# A31C15x register map
Vendor: ABOV Semiconductor Co., Ltd.; File version: 1.0
CPU: CM0PLUS r0p1, little endian, no MPU, no FPU, VTOR, 2 interrupt priority bits
Registers are 32-bit, read-write, reset 0x0 unless marked. A register's access mark holds for its fields unless they carry their own. Offsets are from the block's base; [hi:lo] are bit positions.

## RTCC — Real-time clock
Base 0x40000900
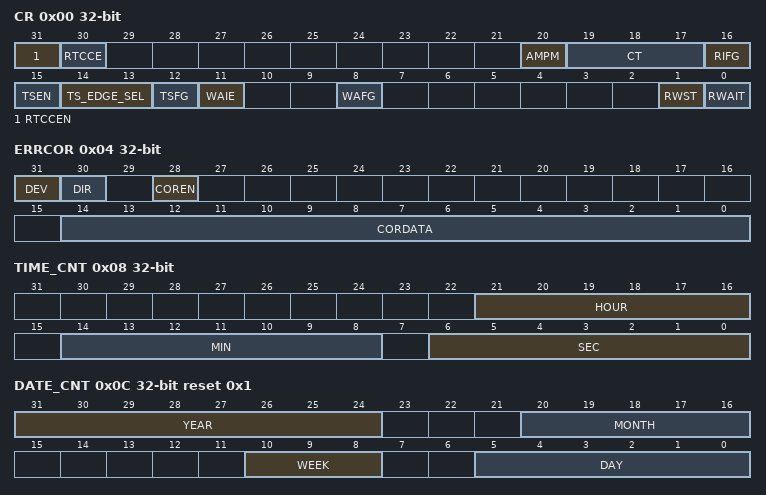
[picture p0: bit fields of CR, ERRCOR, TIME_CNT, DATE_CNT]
0x00 CR — RTCC Control Register
  [31] RTCCEN — RTCC clock input enable
  [30] RTCCE — RTCC counter run
  [20] AMPM — Hour system selection
  [19:17] CT — Period selection of constant-period matching
  [16] RIFG — Constant-period matching flag
  [15] TSEN — Timestamp enable
  [14:13] TS_EDGE_SEL — Timestamp event active edge selection
  [12] TSFG — Time stamp event flag
  [11] WAIE — Alarm enable
  [8] WAFG — Alarm flag
  [1] RWST — RW mode status flag
  [0] RWAIT — RW mode set
0x04 ERRCOR — RTCC Error Correction Register
  [31] DEV — Setting of watch error correction timing.
  [30] DIR — Setting of watch error correction direction
  [28] COREN — Enable watch error correction
  [14:0] CORDATA — Setting of watch error correction data When CORDATA=0, the watch error is not corrected.
0x08 TIME_CNT — RTCC Time Count Register
  [21:16] HOUR — The HOUR register is an 8-bit register that takes a value of 00 to 23 or 01 to 12 and 21 to 32 (decimal) and indicates the count value of hours. It counts up when the minute counter overflows.
  [14:8] MIN — The MIN register is an 8-bit register that takes a value of 0 to 59 (decimal) and indicates the count value of minutes. It counts up when the second counter overflows. When data is written to this register, it is written to a buffer and then to the counter when RWST bit is changed to '0'. Even if the second count register overflows while this register is being written, this register ignores the overflow and is set to the value written. Set a decimal value of 00 to 59 to this register in BCD code. If a value that is not a BCD code is written, it is ignored. If a value outside the range is written, the reset value is set.
  [6:0] SEC — The SEC register is an 8-bit register that takes a value of 0 to 59 (decimal) and indicates the count value of seconds. It counts up when the sub-count register overflows. When data is written to this register, it is written to a buffer and then to the counter when RWST bit is changed to '0'. Set a decimal value of 00 to 59 to this register in BCD code. If a value that is not a BCD code is written, it is ignored. If a value outside the range is written, the reset value is set.
0x0C DATE_CNT reset 0x1 — RTCC Date Count Register
  [31:24] YEAR — The YEAR register is an 8-bit register that takes a value of 0 to 99 (decimal) and indicates the count value of years.
  [20:16] MONTH — The MONTH register is an 8-bit register that takes a value of 1 to 12 (decimal) and indicates the count value of months. It counts up when the day counter overflows.
  [10:8] WEEK — The WEEK register is an 8-bit register that takes a value of 0 to 6 (decimal) and indicates the count value of weekdays. It counts up in synchronization with the day counter.
  [5:0] DAY — The DAY register is an 8-bit register that takes a value of 1 to 31 (decimal) and indicates the count value of days. It counts up when the hour counter overflows.
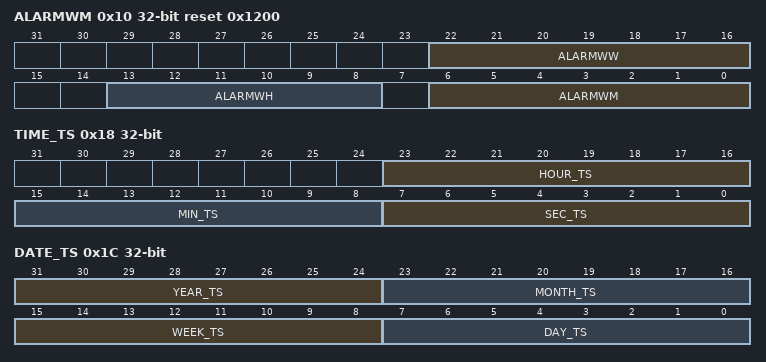
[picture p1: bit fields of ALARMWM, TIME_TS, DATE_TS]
0x10 ALARMWM reset 0x1200 — RTCC Alarm Register
  [22:16] ALARMWW — This register is used to set day of the week for the alarm. Each of the seven bits represents a day of the week, so that duplicate days of the week can be selected.
  [13:8] ALARMWH — This register is used to set hours of the alarm. Set a decimal value of 00 to 23, 01 to 12, or 21 to 32 to this register according to AMPM in BCD code. If a value outside the range is set, the alarm is not detected.
  [6:0] ALARMWM — This register is used to set minutes of the alarm. Set a decimal value of 00 to 59 to this register in BCD code. If a value outside the range is set, the alarm is not detected.
0x14 SUBDR reset 0x1FFFF — RTCC Sub-second counter Compare Reigster
  [15:0] SUBDR — Sub-second counter Compare Reigster
0x18 TIME_TS — TimeStamp Time Reigster
  [23:16] HOUR_TS — HOUR stored when the timestamp event occurred
  [15:8] MIN_TS — MIN stored when the timestamp event occurred
  [7:0] SEC_TS — SEC stored when the timestamp event occurred
0x1C DATE_TS — TimeStamp Date Reigster
  [31:24] YEAR_TS — YEAR stored when the timestamp event occurred
  [23:16] MONTH_TS — MONTH stored when the timestamp event occurred
  [15:8] WEEK_TS — WEEK stored when the timestamp event occurred
  [7:0] DAY_TS — DAY stored when the timestamp event occurred
